VERSION ""

NS_ :

BS_:

BU_:

BO_ 1823 node_id_discover: 1 Vector__XXX
 SG_ session_id : 0|8@1+ (1,0) [0|255] "" Vector__XXX

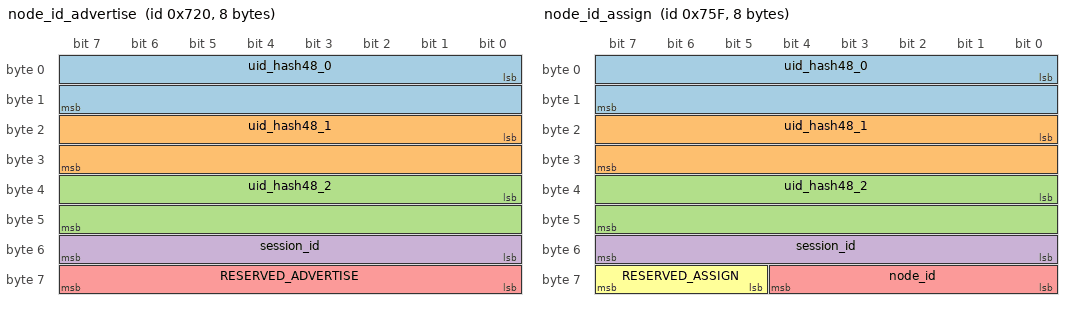
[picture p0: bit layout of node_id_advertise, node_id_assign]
BO_ 1824 node_id_advertise: 8 Vector__XXX
 SG_ uid_hash48_0 : 0|16@1+  (1,0) [0|65535] "hash48_0" Vector__XXX
 SG_ uid_hash48_1 : 16|16@1+ (1,0) [0|65535] "hash48_1" Vector__XXX
 SG_ uid_hash48_2 : 32|16@1+ (1,0) [0|65535] "hash48_2" Vector__XXX
 SG_ session_id : 48|8@1+ (1,0) [0|255] "session_id" Vector__XXX
 SG_ RESERVED_ADVERTISE : 56|8@1+ (1,0) [0|255] "" Vector__XXX

BO_ 1887 node_id_assign: 8 Vector__XXX
 SG_ uid_hash48_0 : 0|16@1+  (1,0) [0|65535] "hash48_0" Vector__XXX
 SG_ uid_hash48_1 : 16|16@1+ (1,0) [0|65535] "hash48_1" Vector__XXX
 SG_ uid_hash48_2 : 32|16@1+ (1,0) [0|65535] "hash48_2" Vector__XXX
 SG_ session_id : 48|8@1+ (1,0) [0|255] "session_id" Vector__XXX
 SG_ node_id : 56|5@1+ (1,0) [0|31] "node_id" Vector__XXX
 SG_ RESERVED_ASSIGN : 61|3@1+ (1,0) [0|7] "" Vector__XXX

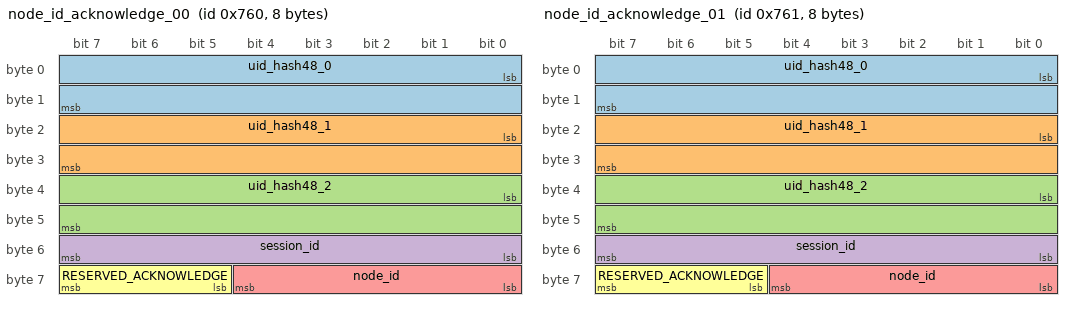
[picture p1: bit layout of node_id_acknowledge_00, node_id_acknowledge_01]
BO_ 1888 node_id_acknowledge_00: 8 Vector__XXX
 SG_ uid_hash48_0 : 0|16@1+  (1,0) [0|65535] "hash48_0" Vector__XXX
 SG_ uid_hash48_1 : 16|16@1+ (1,0) [0|65535] "hash48_1" Vector__XXX
 SG_ uid_hash48_2 : 32|16@1+ (1,0) [0|65535] "hash48_2" Vector__XXX
 SG_ session_id : 48|8@1+ (1,0) [0|255] "session_id" Vector__XXX
 SG_ node_id : 56|5@1+ (1,0) [0|31] "node_id" Vector__XXX
 SG_ RESERVED_ACKNOWLEDGE : 61|3@1+ (1,0) [0|7] "" Vector__XXX

BO_ 1889 node_id_acknowledge_01: 8 Vector__XXX
 SG_ uid_hash48_0 : 0|16@1+  (1,0) [0|65535] "hash48_0" Vector__XXX
 SG_ uid_hash48_1 : 16|16@1+ (1,0) [0|65535] "hash48_1" Vector__XXX
 SG_ uid_hash48_2 : 32|16@1+ (1,0) [0|65535] "hash48_2" Vector__XXX
 SG_ session_id : 48|8@1+ (1,0) [0|255] "session_id" Vector__XXX
 SG_ node_id : 56|5@1+ (1,0) [0|31] "node_id" Vector__XXX
 SG_ RESERVED_ACKNOWLEDGE : 61|3@1+ (1,0) [0|7] "" Vector__XXX

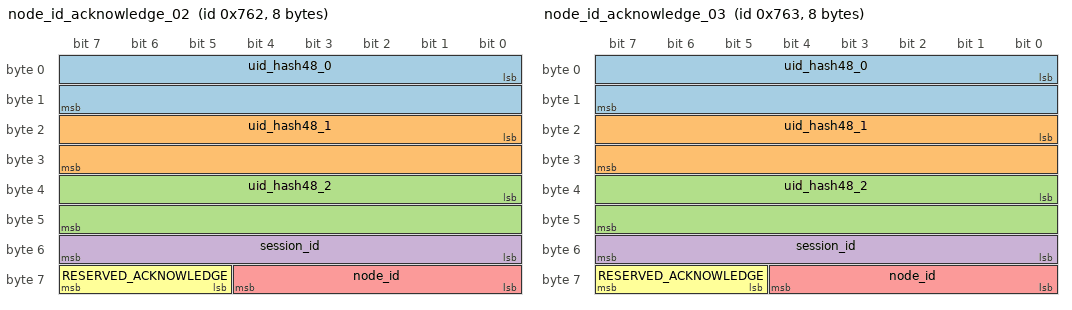
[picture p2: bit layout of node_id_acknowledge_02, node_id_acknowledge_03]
BO_ 1890 node_id_acknowledge_02: 8 Vector__XXX
 SG_ uid_hash48_0 : 0|16@1+  (1,0) [0|65535] "hash48_0" Vector__XXX
 SG_ uid_hash48_1 : 16|16@1+ (1,0) [0|65535] "hash48_1" Vector__XXX
 SG_ uid_hash48_2 : 32|16@1+ (1,0) [0|65535] "hash48_2" Vector__XXX
 SG_ session_id : 48|8@1+ (1,0) [0|255] "session_id" Vector__XXX
 SG_ node_id : 56|5@1+ (1,0) [0|31] "node_id" Vector__XXX
 SG_ RESERVED_ACKNOWLEDGE : 61|3@1+ (1,0) [0|7] "" Vector__XXX

BO_ 1891 node_id_acknowledge_03: 8 Vector__XXX
 SG_ uid_hash48_0 : 0|16@1+  (1,0) [0|65535] "hash48_0" Vector__XXX
 SG_ uid_hash48_1 : 16|16@1+ (1,0) [0|65535] "hash48_1" Vector__XXX
 SG_ uid_hash48_2 : 32|16@1+ (1,0) [0|65535] "hash48_2" Vector__XXX
 SG_ session_id : 48|8@1+ (1,0) [0|255] "session_id" Vector__XXX
 SG_ node_id : 56|5@1+ (1,0) [0|31] "node_id" Vector__XXX
 SG_ RESERVED_ACKNOWLEDGE : 61|3@1+ (1,0) [0|7] "" Vector__XXX

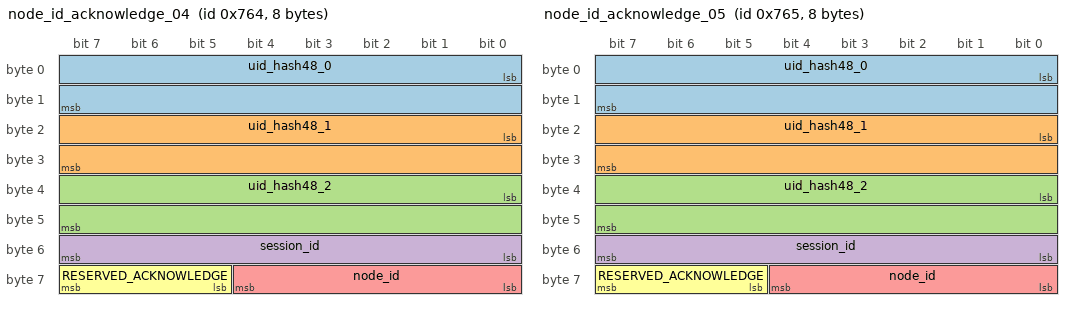
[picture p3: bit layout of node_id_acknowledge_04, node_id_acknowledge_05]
BO_ 1892 node_id_acknowledge_04: 8 Vector__XXX
 SG_ uid_hash48_0 : 0|16@1+  (1,0) [0|65535] "hash48_0" Vector__XXX
 SG_ uid_hash48_1 : 16|16@1+ (1,0) [0|65535] "hash48_1" Vector__XXX
 SG_ uid_hash48_2 : 32|16@1+ (1,0) [0|65535] "hash48_2" Vector__XXX
 SG_ session_id : 48|8@1+ (1,0) [0|255] "session_id" Vector__XXX
 SG_ node_id : 56|5@1+ (1,0) [0|31] "node_id" Vector__XXX
 SG_ RESERVED_ACKNOWLEDGE : 61|3@1+ (1,0) [0|7] "" Vector__XXX

BO_ 1893 node_id_acknowledge_05: 8 Vector__XXX
 SG_ uid_hash48_0 : 0|16@1+  (1,0) [0|65535] "hash48_0" Vector__XXX
 SG_ uid_hash48_1 : 16|16@1+ (1,0) [0|65535] "hash48_1" Vector__XXX
 SG_ uid_hash48_2 : 32|16@1+ (1,0) [0|65535] "hash48_2" Vector__XXX
 SG_ session_id : 48|8@1+ (1,0) [0|255] "session_id" Vector__XXX
 SG_ node_id : 56|5@1+ (1,0) [0|31] "node_id" Vector__XXX
 SG_ RESERVED_ACKNOWLEDGE : 61|3@1+ (1,0) [0|7] "" Vector__XXX

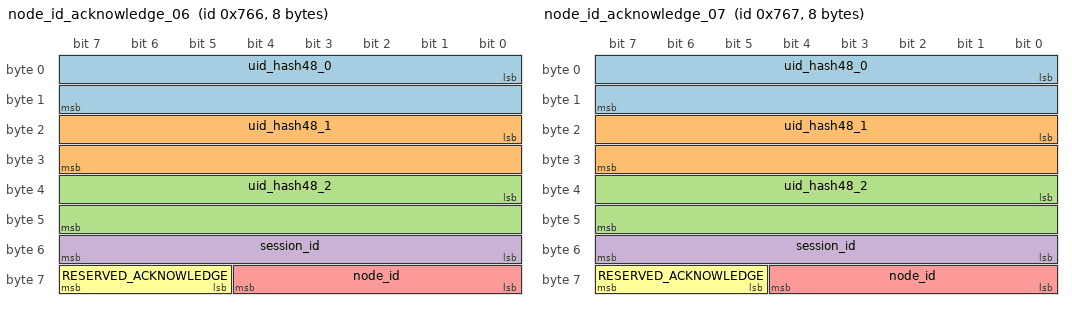
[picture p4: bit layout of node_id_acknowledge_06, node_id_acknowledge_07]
BO_ 1894 node_id_acknowledge_06: 8 Vector__XXX
 SG_ uid_hash48_0 : 0|16@1+  (1,0) [0|65535] "hash48_0" Vector__XXX
 SG_ uid_hash48_1 : 16|16@1+ (1,0) [0|65535] "hash48_1" Vector__XXX
 SG_ uid_hash48_2 : 32|16@1+ (1,0) [0|65535] "hash48_2" Vector__XXX
 SG_ session_id : 48|8@1+ (1,0) [0|255] "session_id" Vector__XXX
 SG_ node_id : 56|5@1+ (1,0) [0|31] "node_id" Vector__XXX
 SG_ RESERVED_ACKNOWLEDGE : 61|3@1+ (1,0) [0|7] "" Vector__XXX

BO_ 1895 node_id_acknowledge_07: 8 Vector__XXX
 SG_ uid_hash48_0 : 0|16@1+  (1,0) [0|65535] "hash48_0" Vector__XXX
 SG_ uid_hash48_1 : 16|16@1+ (1,0) [0|65535] "hash48_1" Vector__XXX
 SG_ uid_hash48_2 : 32|16@1+ (1,0) [0|65535] "hash48_2" Vector__XXX
 SG_ session_id : 48|8@1+ (1,0) [0|255] "session_id" Vector__XXX
 SG_ node_id : 56|5@1+ (1,0) [0|31] "node_id" Vector__XXX
 SG_ RESERVED_ACKNOWLEDGE : 61|3@1+ (1,0) [0|7] "" Vector__XXX

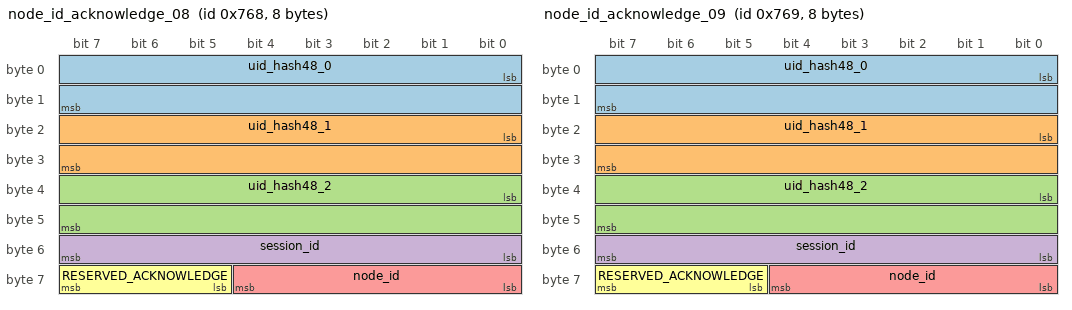
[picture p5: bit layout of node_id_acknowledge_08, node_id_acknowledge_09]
BO_ 1896 node_id_acknowledge_08: 8 Vector__XXX
 SG_ uid_hash48_0 : 0|16@1+  (1,0) [0|65535] "hash48_0" Vector__XXX
 SG_ uid_hash48_1 : 16|16@1+ (1,0) [0|65535] "hash48_1" Vector__XXX
 SG_ uid_hash48_2 : 32|16@1+ (1,0) [0|65535] "hash48_2" Vector__XXX
 SG_ session_id : 48|8@1+ (1,0) [0|255] "session_id" Vector__XXX
 SG_ node_id : 56|5@1+ (1,0) [0|31] "node_id" Vector__XXX
 SG_ RESERVED_ACKNOWLEDGE : 61|3@1+ (1,0) [0|7] "" Vector__XXX

BO_ 1897 node_id_acknowledge_09: 8 Vector__XXX
 SG_ uid_hash48_0 : 0|16@1+  (1,0) [0|65535] "hash48_0" Vector__XXX
 SG_ uid_hash48_1 : 16|16@1+ (1,0) [0|65535] "hash48_1" Vector__XXX
 SG_ uid_hash48_2 : 32|16@1+ (1,0) [0|65535] "hash48_2" Vector__XXX
 SG_ session_id : 48|8@1+ (1,0) [0|255] "session_id" Vector__XXX
 SG_ node_id : 56|5@1+ (1,0) [0|31] "node_id" Vector__XXX
 SG_ RESERVED_ACKNOWLEDGE : 61|3@1+ (1,0) [0|7] "" Vector__XXX

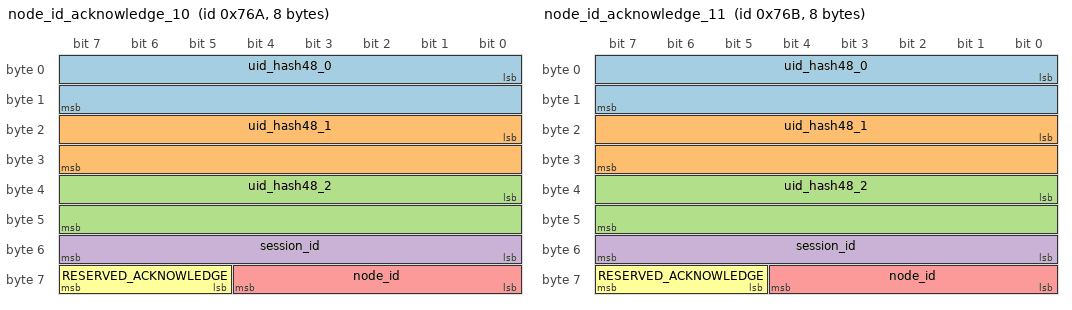
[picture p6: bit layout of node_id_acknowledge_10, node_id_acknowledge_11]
BO_ 1898 node_id_acknowledge_10: 8 Vector__XXX
 SG_ uid_hash48_0 : 0|16@1+  (1,0) [0|65535] "hash48_0" Vector__XXX
 SG_ uid_hash48_1 : 16|16@1+ (1,0) [0|65535] "hash48_1" Vector__XXX
 SG_ uid_hash48_2 : 32|16@1+ (1,0) [0|65535] "hash48_2" Vector__XXX
 SG_ session_id : 48|8@1+ (1,0) [0|255] "session_id" Vector__XXX
 SG_ node_id : 56|5@1+ (1,0) [0|31] "node_id" Vector__XXX
 SG_ RESERVED_ACKNOWLEDGE : 61|3@1+ (1,0) [0|7] "" Vector__XXX

BO_ 1899 node_id_acknowledge_11: 8 Vector__XXX
 SG_ uid_hash48_0 : 0|16@1+  (1,0) [0|65535] "hash48_0" Vector__XXX
 SG_ uid_hash48_1 : 16|16@1+ (1,0) [0|65535] "hash48_1" Vector__XXX
 SG_ uid_hash48_2 : 32|16@1+ (1,0) [0|65535] "hash48_2" Vector__XXX
 SG_ session_id : 48|8@1+ (1,0) [0|255] "session_id" Vector__XXX
 SG_ node_id : 56|5@1+ (1,0) [0|31] "node_id" Vector__XXX
 SG_ RESERVED_ACKNOWLEDGE : 61|3@1+ (1,0) [0|7] "" Vector__XXX

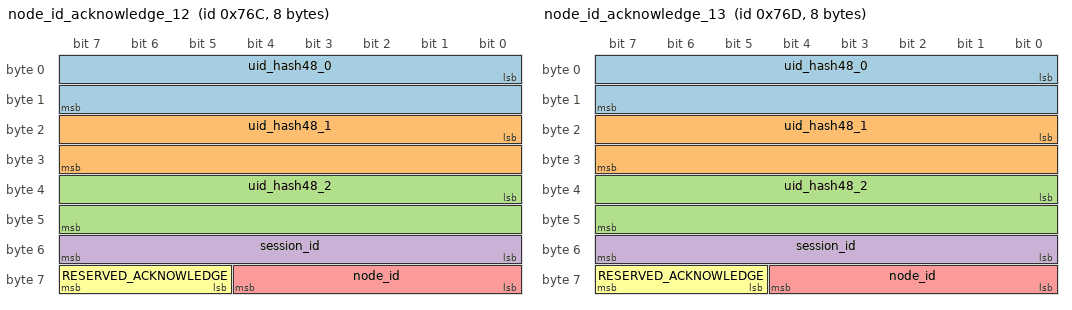
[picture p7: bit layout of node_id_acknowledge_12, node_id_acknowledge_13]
BO_ 1900 node_id_acknowledge_12: 8 Vector__XXX
 SG_ uid_hash48_0 : 0|16@1+  (1,0) [0|65535] "hash48_0" Vector__XXX
 SG_ uid_hash48_1 : 16|16@1+ (1,0) [0|65535] "hash48_1" Vector__XXX
 SG_ uid_hash48_2 : 32|16@1+ (1,0) [0|65535] "hash48_2" Vector__XXX
 SG_ session_id : 48|8@1+ (1,0) [0|255] "session_id" Vector__XXX
 SG_ node_id : 56|5@1+ (1,0) [0|31] "node_id" Vector__XXX
 SG_ RESERVED_ACKNOWLEDGE : 61|3@1+ (1,0) [0|7] "" Vector__XXX

BO_ 1901 node_id_acknowledge_13: 8 Vector__XXX
 SG_ uid_hash48_0 : 0|16@1+  (1,0) [0|65535] "hash48_0" Vector__XXX
 SG_ uid_hash48_1 : 16|16@1+ (1,0) [0|65535] "hash48_1" Vector__XXX
 SG_ uid_hash48_2 : 32|16@1+ (1,0) [0|65535] "hash48_2" Vector__XXX
 SG_ session_id : 48|8@1+ (1,0) [0|255] "session_id" Vector__XXX
 SG_ node_id : 56|5@1+ (1,0) [0|31] "node_id" Vector__XXX
 SG_ RESERVED_ACKNOWLEDGE : 61|3@1+ (1,0) [0|7] "" Vector__XXX

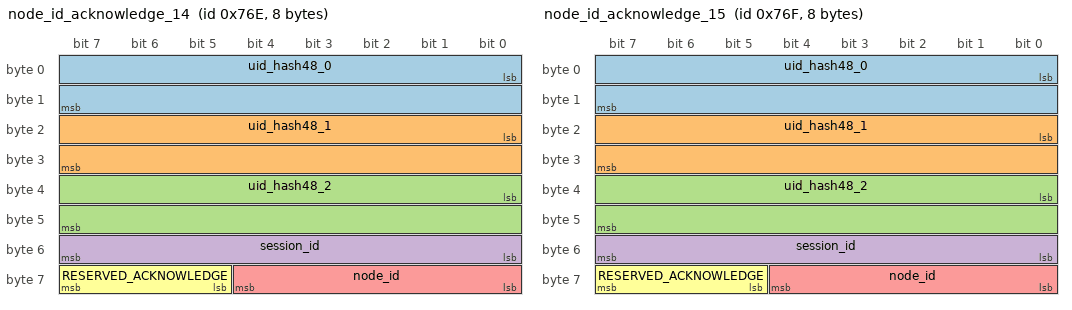
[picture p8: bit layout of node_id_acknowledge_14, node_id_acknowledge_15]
BO_ 1902 node_id_acknowledge_14: 8 Vector__XXX
 SG_ uid_hash48_0 : 0|16@1+  (1,0) [0|65535] "hash48_0" Vector__XXX
 SG_ uid_hash48_1 : 16|16@1+ (1,0) [0|65535] "hash48_1" Vector__XXX
 SG_ uid_hash48_2 : 32|16@1+ (1,0) [0|65535] "hash48_2" Vector__XXX
 SG_ session_id : 48|8@1+ (1,0) [0|255] "session_id" Vector__XXX
 SG_ node_id : 56|5@1+ (1,0) [0|31] "node_id" Vector__XXX
 SG_ RESERVED_ACKNOWLEDGE : 61|3@1+ (1,0) [0|7] "" Vector__XXX

BO_ 1903 node_id_acknowledge_15: 8 Vector__XXX
 SG_ uid_hash48_0 : 0|16@1+  (1,0) [0|65535] "hash48_0" Vector__XXX
 SG_ uid_hash48_1 : 16|16@1+ (1,0) [0|65535] "hash48_1" Vector__XXX
 SG_ uid_hash48_2 : 32|16@1+ (1,0) [0|65535] "hash48_2" Vector__XXX
 SG_ session_id : 48|8@1+ (1,0) [0|255] "session_id" Vector__XXX
 SG_ node_id : 56|5@1+ (1,0) [0|31] "node_id" Vector__XXX
 SG_ RESERVED_ACKNOWLEDGE : 61|3@1+ (1,0) [0|7] "" Vector__XXX

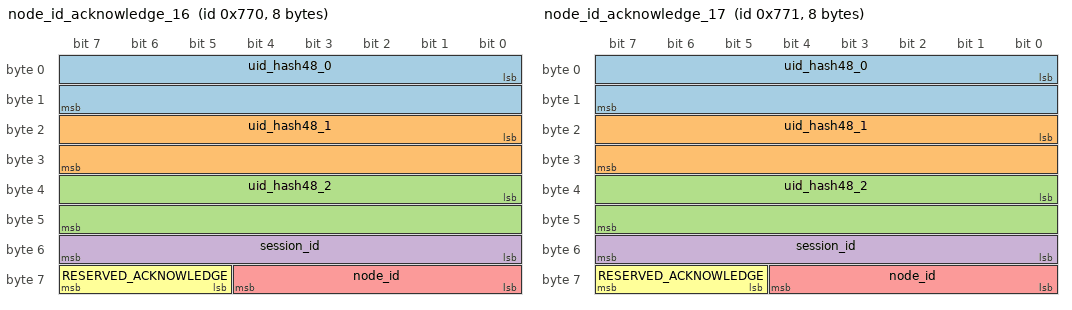
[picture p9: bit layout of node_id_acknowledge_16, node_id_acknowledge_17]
BO_ 1904 node_id_acknowledge_16: 8 Vector__XXX
 SG_ uid_hash48_0 : 0|16@1+  (1,0) [0|65535] "hash48_0" Vector__XXX
 SG_ uid_hash48_1 : 16|16@1+ (1,0) [0|65535] "hash48_1" Vector__XXX
 SG_ uid_hash48_2 : 32|16@1+ (1,0) [0|65535] "hash48_2" Vector__XXX
 SG_ session_id : 48|8@1+ (1,0) [0|255] "session_id" Vector__XXX
 SG_ node_id : 56|5@1+ (1,0) [0|31] "node_id" Vector__XXX
 SG_ RESERVED_ACKNOWLEDGE : 61|3@1+ (1,0) [0|7] "" Vector__XXX

BO_ 1905 node_id_acknowledge_17: 8 Vector__XXX
 SG_ uid_hash48_0 : 0|16@1+  (1,0) [0|65535] "hash48_0" Vector__XXX
 SG_ uid_hash48_1 : 16|16@1+ (1,0) [0|65535] "hash48_1" Vector__XXX
 SG_ uid_hash48_2 : 32|16@1+ (1,0) [0|65535] "hash48_2" Vector__XXX
 SG_ session_id : 48|8@1+ (1,0) [0|255] "session_id" Vector__XXX
 SG_ node_id : 56|5@1+ (1,0) [0|31] "node_id" Vector__XXX
 SG_ RESERVED_ACKNOWLEDGE : 61|3@1+ (1,0) [0|7] "" Vector__XXX

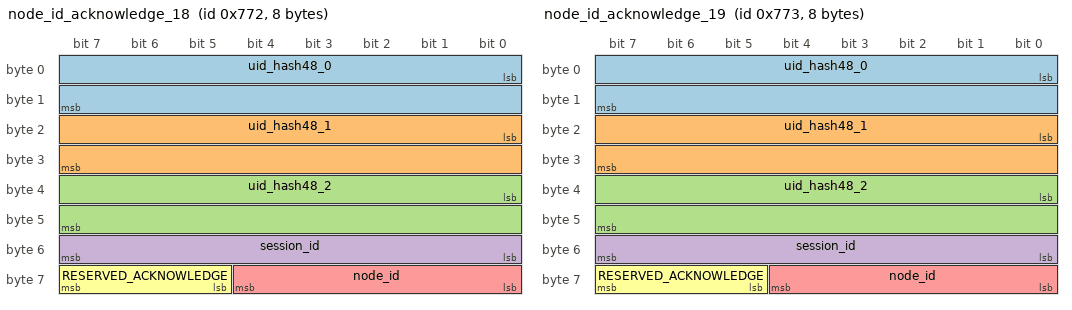
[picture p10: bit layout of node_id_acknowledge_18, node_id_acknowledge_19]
BO_ 1906 node_id_acknowledge_18: 8 Vector__XXX
 SG_ uid_hash48_0 : 0|16@1+  (1,0) [0|65535] "hash48_0" Vector__XXX
 SG_ uid_hash48_1 : 16|16@1+ (1,0) [0|65535] "hash48_1" Vector__XXX
 SG_ uid_hash48_2 : 32|16@1+ (1,0) [0|65535] "hash48_2" Vector__XXX
 SG_ session_id : 48|8@1+ (1,0) [0|255] "session_id" Vector__XXX
 SG_ node_id : 56|5@1+ (1,0) [0|31] "node_id" Vector__XXX
 SG_ RESERVED_ACKNOWLEDGE : 61|3@1+ (1,0) [0|7] "" Vector__XXX

BO_ 1907 node_id_acknowledge_19: 8 Vector__XXX
 SG_ uid_hash48_0 : 0|16@1+  (1,0) [0|65535] "hash48_0" Vector__XXX
 SG_ uid_hash48_1 : 16|16@1+ (1,0) [0|65535] "hash48_1" Vector__XXX
 SG_ uid_hash48_2 : 32|16@1+ (1,0) [0|65535] "hash48_2" Vector__XXX
 SG_ session_id : 48|8@1+ (1,0) [0|255] "session_id" Vector__XXX
 SG_ node_id : 56|5@1+ (1,0) [0|31] "node_id" Vector__XXX
 SG_ RESERVED_ACKNOWLEDGE : 61|3@1+ (1,0) [0|7] "" Vector__XXX

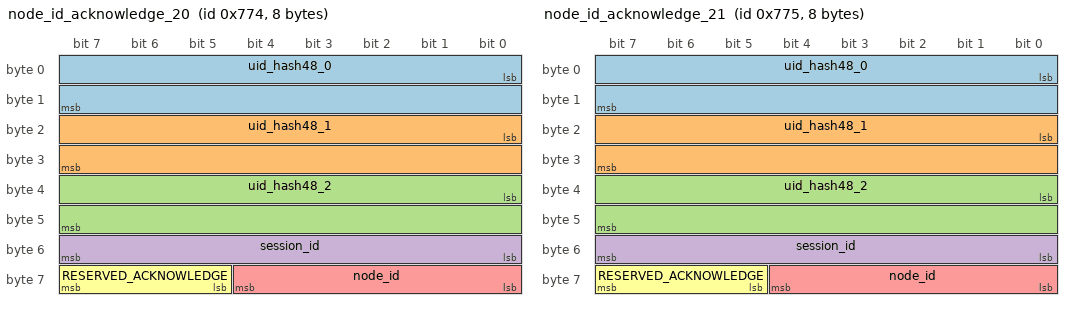
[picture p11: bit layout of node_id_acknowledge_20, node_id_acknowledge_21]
BO_ 1908 node_id_acknowledge_20: 8 Vector__XXX
 SG_ uid_hash48_0 : 0|16@1+  (1,0) [0|65535] "hash48_0" Vector__XXX
 SG_ uid_hash48_1 : 16|16@1+ (1,0) [0|65535] "hash48_1" Vector__XXX
 SG_ uid_hash48_2 : 32|16@1+ (1,0) [0|65535] "hash48_2" Vector__XXX
 SG_ session_id : 48|8@1+ (1,0) [0|255] "session_id" Vector__XXX
 SG_ node_id : 56|5@1+ (1,0) [0|31] "node_id" Vector__XXX
 SG_ RESERVED_ACKNOWLEDGE : 61|3@1+ (1,0) [0|7] "" Vector__XXX

BO_ 1909 node_id_acknowledge_21: 8 Vector__XXX
 SG_ uid_hash48_0 : 0|16@1+  (1,0) [0|65535] "hash48_0" Vector__XXX
 SG_ uid_hash48_1 : 16|16@1+ (1,0) [0|65535] "hash48_1" Vector__XXX
 SG_ uid_hash48_2 : 32|16@1+ (1,0) [0|65535] "hash48_2" Vector__XXX
 SG_ session_id : 48|8@1+ (1,0) [0|255] "session_id" Vector__XXX
 SG_ node_id : 56|5@1+ (1,0) [0|31] "node_id" Vector__XXX
 SG_ RESERVED_ACKNOWLEDGE : 61|3@1+ (1,0) [0|7] "" Vector__XXX

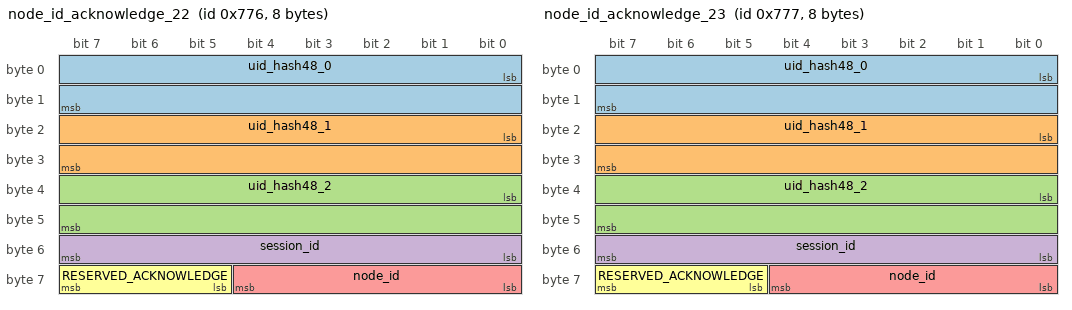
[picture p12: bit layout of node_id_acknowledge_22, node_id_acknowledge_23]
BO_ 1910 node_id_acknowledge_22: 8 Vector__XXX
 SG_ uid_hash48_0 : 0|16@1+  (1,0) [0|65535] "hash48_0" Vector__XXX
 SG_ uid_hash48_1 : 16|16@1+ (1,0) [0|65535] "hash48_1" Vector__XXX
 SG_ uid_hash48_2 : 32|16@1+ (1,0) [0|65535] "hash48_2" Vector__XXX
 SG_ session_id : 48|8@1+ (1,0) [0|255] "session_id" Vector__XXX
 SG_ node_id : 56|5@1+ (1,0) [0|31] "node_id" Vector__XXX
 SG_ RESERVED_ACKNOWLEDGE : 61|3@1+ (1,0) [0|7] "" Vector__XXX

BO_ 1911 node_id_acknowledge_23: 8 Vector__XXX
 SG_ uid_hash48_0 : 0|16@1+  (1,0) [0|65535] "hash48_0" Vector__XXX
 SG_ uid_hash48_1 : 16|16@1+ (1,0) [0|65535] "hash48_1" Vector__XXX
 SG_ uid_hash48_2 : 32|16@1+ (1,0) [0|65535] "hash48_2" Vector__XXX
 SG_ session_id : 48|8@1+ (1,0) [0|255] "session_id" Vector__XXX
 SG_ node_id : 56|5@1+ (1,0) [0|31] "node_id" Vector__XXX
 SG_ RESERVED_ACKNOWLEDGE : 61|3@1+ (1,0) [0|7] "" Vector__XXX

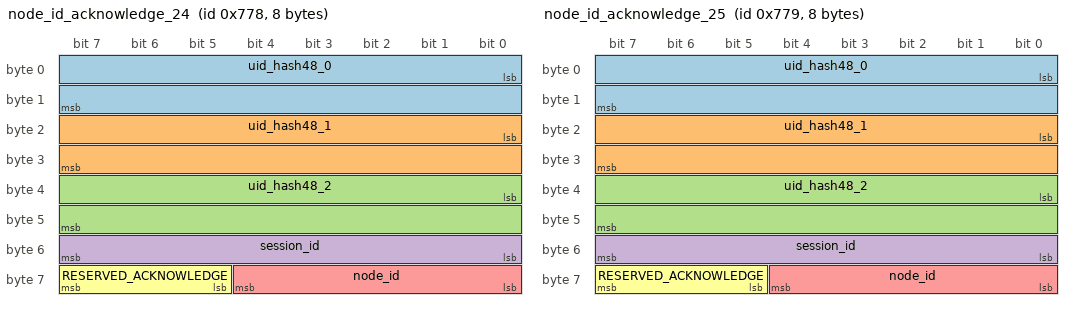
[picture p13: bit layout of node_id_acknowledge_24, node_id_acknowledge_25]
BO_ 1912 node_id_acknowledge_24: 8 Vector__XXX
 SG_ uid_hash48_0 : 0|16@1+  (1,0) [0|65535] "hash48_0" Vector__XXX
 SG_ uid_hash48_1 : 16|16@1+ (1,0) [0|65535] "hash48_1" Vector__XXX
 SG_ uid_hash48_2 : 32|16@1+ (1,0) [0|65535] "hash48_2" Vector__XXX
 SG_ session_id : 48|8@1+ (1,0) [0|255] "session_id" Vector__XXX
 SG_ node_id : 56|5@1+ (1,0) [0|31] "node_id" Vector__XXX
 SG_ RESERVED_ACKNOWLEDGE : 61|3@1+ (1,0) [0|7] "" Vector__XXX

BO_ 1913 node_id_acknowledge_25: 8 Vector__XXX
 SG_ uid_hash48_0 : 0|16@1+  (1,0) [0|65535] "hash48_0" Vector__XXX
 SG_ uid_hash48_1 : 16|16@1+ (1,0) [0|65535] "hash48_1" Vector__XXX
 SG_ uid_hash48_2 : 32|16@1+ (1,0) [0|65535] "hash48_2" Vector__XXX
 SG_ session_id : 48|8@1+ (1,0) [0|255] "session_id" Vector__XXX
 SG_ node_id : 56|5@1+ (1,0) [0|31] "node_id" Vector__XXX
 SG_ RESERVED_ACKNOWLEDGE : 61|3@1+ (1,0) [0|7] "" Vector__XXX

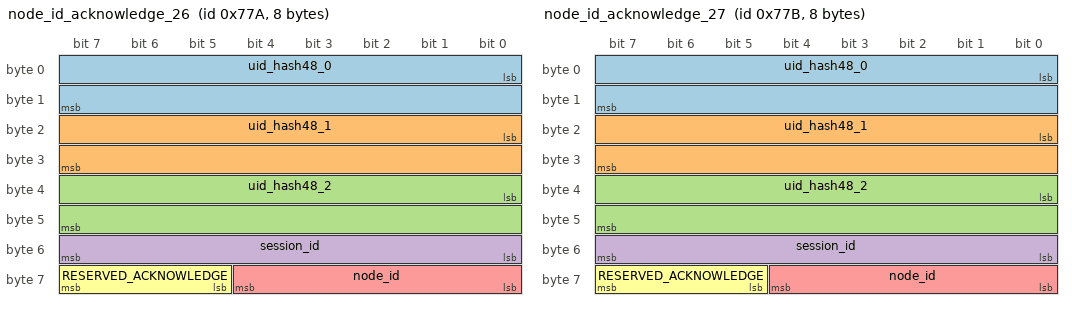
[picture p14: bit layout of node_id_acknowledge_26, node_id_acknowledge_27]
BO_ 1914 node_id_acknowledge_26: 8 Vector__XXX
 SG_ uid_hash48_0 : 0|16@1+  (1,0) [0|65535] "hash48_0" Vector__XXX
 SG_ uid_hash48_1 : 16|16@1+ (1,0) [0|65535] "hash48_1" Vector__XXX
 SG_ uid_hash48_2 : 32|16@1+ (1,0) [0|65535] "hash48_2" Vector__XXX
 SG_ session_id : 48|8@1+ (1,0) [0|255] "session_id" Vector__XXX
 SG_ node_id : 56|5@1+ (1,0) [0|31] "node_id" Vector__XXX
 SG_ RESERVED_ACKNOWLEDGE : 61|3@1+ (1,0) [0|7] "" Vector__XXX

BO_ 1915 node_id_acknowledge_27: 8 Vector__XXX
 SG_ uid_hash48_0 : 0|16@1+  (1,0) [0|65535] "hash48_0" Vector__XXX
 SG_ uid_hash48_1 : 16|16@1+ (1,0) [0|65535] "hash48_1" Vector__XXX
 SG_ uid_hash48_2 : 32|16@1+ (1,0) [0|65535] "hash48_2" Vector__XXX
 SG_ session_id : 48|8@1+ (1,0) [0|255] "session_id" Vector__XXX
 SG_ node_id : 56|5@1+ (1,0) [0|31] "node_id" Vector__XXX
 SG_ RESERVED_ACKNOWLEDGE : 61|3@1+ (1,0) [0|7] "" Vector__XXX

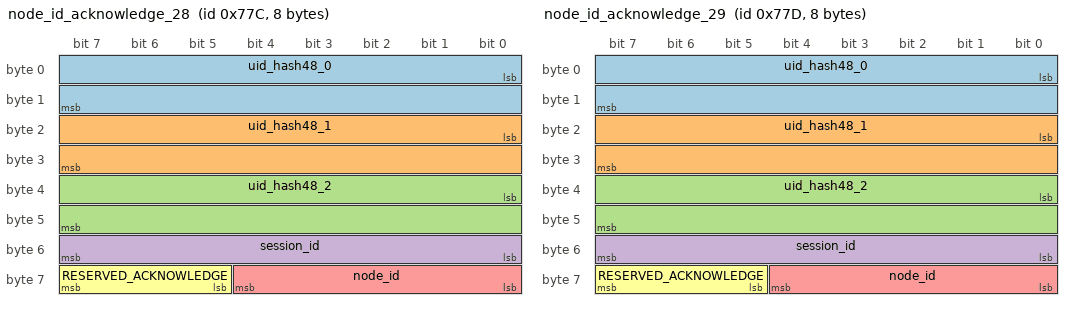
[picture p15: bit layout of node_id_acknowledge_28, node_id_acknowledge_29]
BO_ 1916 node_id_acknowledge_28: 8 Vector__XXX
 SG_ uid_hash48_0 : 0|16@1+  (1,0) [0|65535] "hash48_0" Vector__XXX
 SG_ uid_hash48_1 : 16|16@1+ (1,0) [0|65535] "hash48_1" Vector__XXX
 SG_ uid_hash48_2 : 32|16@1+ (1,0) [0|65535] "hash48_2" Vector__XXX
 SG_ session_id : 48|8@1+ (1,0) [0|255] "session_id" Vector__XXX
 SG_ node_id : 56|5@1+ (1,0) [0|31] "node_id" Vector__XXX
 SG_ RESERVED_ACKNOWLEDGE : 61|3@1+ (1,0) [0|7] "" Vector__XXX

BO_ 1917 node_id_acknowledge_29: 8 Vector__XXX
 SG_ uid_hash48_0 : 0|16@1+  (1,0) [0|65535] "hash48_0" Vector__XXX
 SG_ uid_hash48_1 : 16|16@1+ (1,0) [0|65535] "hash48_1" Vector__XXX
 SG_ uid_hash48_2 : 32|16@1+ (1,0) [0|65535] "hash48_2" Vector__XXX
 SG_ session_id : 48|8@1+ (1,0) [0|255] "session_id" Vector__XXX
 SG_ node_id : 56|5@1+ (1,0) [0|31] "node_id" Vector__XXX
 SG_ RESERVED_ACKNOWLEDGE : 61|3@1+ (1,0) [0|7] "" Vector__XXX

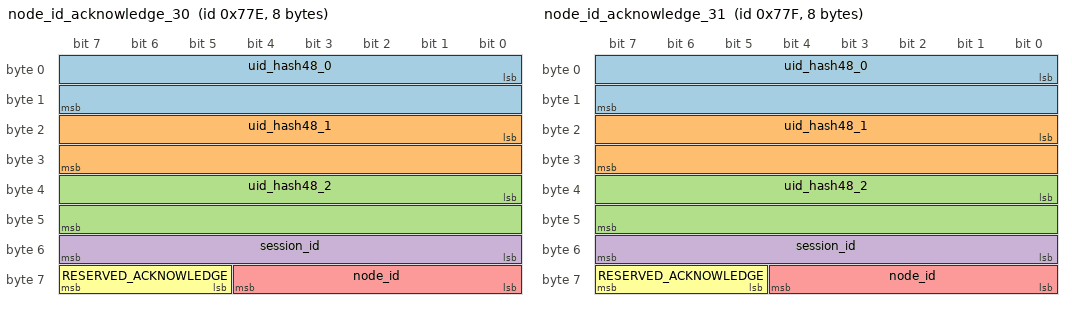
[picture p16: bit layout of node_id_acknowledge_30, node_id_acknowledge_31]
BO_ 1918 node_id_acknowledge_30: 8 Vector__XXX
 SG_ uid_hash48_0 : 0|16@1+  (1,0) [0|65535] "hash48_0" Vector__XXX
 SG_ uid_hash48_1 : 16|16@1+ (1,0) [0|65535] "hash48_1" Vector__XXX
 SG_ uid_hash48_2 : 32|16@1+ (1,0) [0|65535] "hash48_2" Vector__XXX
 SG_ session_id : 48|8@1+ (1,0) [0|255] "session_id" Vector__XXX
 SG_ node_id : 56|5@1+ (1,0) [0|31] "node_id" Vector__XXX
 SG_ RESERVED_ACKNOWLEDGE : 61|3@1+ (1,0) [0|7] "" Vector__XXX

BO_ 1919 node_id_acknowledge_31: 8 Vector__XXX
 SG_ uid_hash48_0 : 0|16@1+  (1,0) [0|65535] "hash48_0" Vector__XXX
 SG_ uid_hash48_1 : 16|16@1+ (1,0) [0|65535] "hash48_1" Vector__XXX
 SG_ uid_hash48_2 : 32|16@1+ (1,0) [0|65535] "hash48_2" Vector__XXX
 SG_ session_id : 48|8@1+ (1,0) [0|255] "session_id" Vector__XXX
 SG_ node_id : 56|5@1+ (1,0) [0|31] "node_id" Vector__XXX
 SG_ RESERVED_ACKNOWLEDGE : 61|3@1+ (1,0) [0|7] "" Vector__XXX

BA_DEF_  "BusType" STRING ;
BA_DEF_DEF_  "BusType" "CAN";
